# PCIE0_CORE_VMAP_HP_MMRS register map
Vendor: Texas Instruments
Peripheral module from a debugger description file (folder J7ES).
Registers are 32-bit, read-write, reset 0x0 unless marked. A register's access mark holds for its fields unless they carry their own. Offsets are as the file gives them; lines under a group give offsets from that group; [hi:lo] are bit positions; {n}, {i} and the like mark numbered series; 'fields as' and 'values as' point back to an identical list; <NAME> marks a mode.

## PCIE0_CORE_VMAP_HP_MMRS
0x00 PCIE_VMAP_HP_CTRL_j — Control register Offset = 0h + (j * Ch); where j = 0h to 1Fh
  [0] EN — ID enable
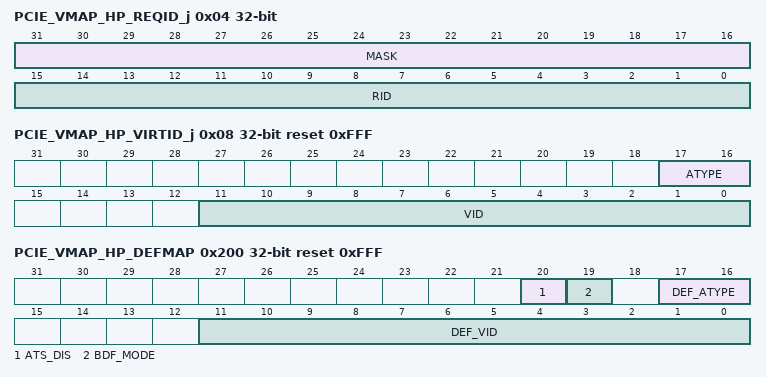
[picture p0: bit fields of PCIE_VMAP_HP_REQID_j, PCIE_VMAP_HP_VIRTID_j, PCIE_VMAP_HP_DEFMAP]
0x04 PCIE_VMAP_HP_REQID_j — Requester ID mask and value register Offset = 4h + (j * Ch); where j = 0h to 1Fh
  [31:16] MASK — RequesterID mask
  [15:0] RID — RequesterID
0x08 PCIE_VMAP_HP_VIRTID_j reset 0xFFF — Virt ID and Atype register Offset = 8h + (j * Ch); where j = 0h to 1Fh
  [17:16] ATYPE — Address type attribute.
  [11:0] VID — Match ID
0x200 PCIE_VMAP_HP_DEFMAP reset 0xFFF — virtID default value register
  [20] ATS_DIS — ATS mode.
  [19] BDF_MODE — Bus default mode.
  [17:16] DEF_ATYPE — Default address type attribute.
  [11:0] DEF_VID — Default match ID
